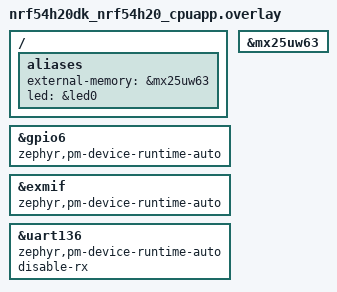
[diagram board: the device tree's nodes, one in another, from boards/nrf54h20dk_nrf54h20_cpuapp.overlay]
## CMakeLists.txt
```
#
# Copyright (c) 2024 Nordic Semiconductor ASA
#
# SPDX-License-Identifier: LicenseRef-Nordic-5-Clause
#

cmake_minimum_required(VERSION 3.20.0)

find_package(Zephyr REQUIRED HINTS $ENV{ZEPHYR_BASE})

if(NOT SYSBUILD)
  message(FATAL_ERROR
    " This is a multi-image application that should be built using sysbuild.\n"
    " Add --sysbuild argument to west build command to prepare all the images."
  )
endif()

project(idle_exmif)

target_sources(app PRIVATE src/main.c)
```

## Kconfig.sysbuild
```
#
# Copyright (c) 2024 Nordic Semiconductor ASA
#
# SPDX-License-Identifier: LicenseRef-Nordic-5-Clause
#

choice NETCORE
	default NETCORE_REMOTE_SLEEP_FOREVER

config NETCORE_REMOTE_SLEEP_FOREVER
	bool "Remote sleep forever image"

endchoice

config NETCORE_IMAGE_NAME
	default "remote_sleep_forever" if NETCORE_REMOTE_SLEEP_FOREVER

config NETCORE_IMAGE_PATH
	default "${ZEPHYR_NRF_MODULE_DIR}/tests/benchmarks/power_consumption/common/remote_sleep_forever" if NETCORE_REMOTE_SLEEP_FOREVER

source "share/sysbuild/Kconfig"
```

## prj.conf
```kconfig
CONFIG_PM=y
CONFIG_PM_DEVICE=y
CONFIG_PM_DEVICE_RUNTIME=y
CONFIG_POWEROFF=y
CONFIG_MSPI=y

CONFIG_FLASH=y
CONFIG_FLASH_JESD216_API=y
CONFIG_FLASH_PAGE_LAYOUT=y

CONFIG_MAIN_STACK_SIZE=8192
CONFIG_UART_ASYNC_API=y

CONFIG_ASSERT=y

# Enable for debugging purposes only
CONFIG_CONSOLE=n
CONFIG_UART_CONSOLE=n
CONFIG_SERIAL=n
```

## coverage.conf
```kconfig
CONFIG_MSPI=y

CONFIG_PM=y
CONFIG_PM_DEVICE=y
CONFIG_PM_DEVICE_RUNTIME=y
CONFIG_POWEROFF=y

CONFIG_BOOT_BANNER=n
CONFIG_NCS_BOOT_BANNER=n
CONFIG_ASSERT=n
CONFIG_CLOCK_CONTROL=n

CONFIG_PRINTK=y
CONFIG_LOG=n
CONFIG_CONSOLE=y
CONFIG_UART_CONSOLE=y

CONFIG_LOG_BUFFER_SIZE=16384
```

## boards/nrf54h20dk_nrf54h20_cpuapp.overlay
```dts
/*
 * Copyright (c) 2026 Nordic Semiconductor ASA
 *
 * SPDX-License-Identifier: LicenseRef-Nordic-5-Clause
 */

/ {
	aliases {
		external-memory = &mx25uw63;
		led = &led0;
		/delete-property/ led1;
	};
};

/delete-node/ &led1;

&gpio6 {
	status = "okay";
	zephyr,pm-device-runtime-auto;
};

&exmif {
	status = "okay";
	zephyr,pm-device-runtime-auto;
};

&mx25uw63 {
	status = "okay";
};

&uart136 {
	zephyr,pm-device-runtime-auto;
	disable-rx;
};
```

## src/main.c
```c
/*
 * Copyright (c) 2026 Nordic Semiconductor ASA
 *
 * SPDX-License-Identifier: LicenseRef-Nordic-5-Clause
 */

#include <zephyr/kernel.h>
#include <zephyr/drivers/flash.h>
#include <zephyr/drivers/gpio.h>

#define SLEEP_TIME_MS 1000
#define ACTIVE_TIME_MS 1000

static const struct device *const flash_dev = DEVICE_DT_GET(DT_ALIAS(external_memory));
static const struct gpio_dt_spec led = GPIO_DT_SPEC_GET(DT_ALIAS(led), gpios);

static uint8_t flash_buffer[512];

K_SEM_DEFINE(timer_expired_sem, 0, 1);

static void timer_handler(struct k_timer *dummy)
{
	(void)dummy;

	k_sem_give(&timer_expired_sem);
}

K_TIMER_DEFINE(timer, timer_handler, NULL);

int main(void)
{
	int ret;

	printk("Multicore idle exmif test on %s\n", CONFIG_BOARD_TARGET);

	ret = device_is_ready(flash_dev);
	__ASSERT(ret == 1, "Flash device not ready\n");

	ret = gpio_is_ready_dt(&led);
	__ASSERT(ret == 1, "GPIO device not ready\n");

	ret = gpio_pin_configure_dt(&led, GPIO_OUTPUT_INACTIVE);
	__ASSERT(ret == 0, "gpio_pin_configure_dt return code: %d\n", ret);

	printk("Test sequence start\n");
	while (1) {

		k_timer_start(&timer, K_MSEC(ACTIVE_TIME_MS), K_NO_WAIT);
		gpio_pin_set_dt(&led, 1);
		while (k_sem_take(&timer_expired_sem, K_NO_WAIT) != 0) {
			ret = flash_read(flash_dev, 0, flash_buffer, sizeof(flash_buffer));
			__ASSERT(ret == 0, "Flash read failed: %d\n", ret);
		}
		gpio_pin_set_dt(&led, 0);
		k_msleep(SLEEP_TIME_MS);
	}

	return 0;
}
```
